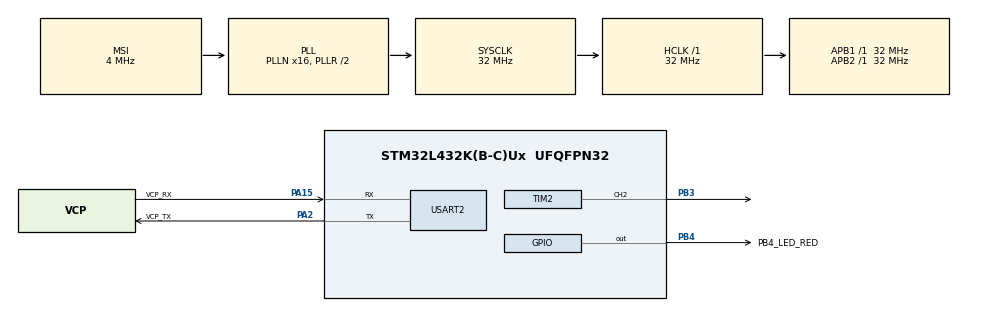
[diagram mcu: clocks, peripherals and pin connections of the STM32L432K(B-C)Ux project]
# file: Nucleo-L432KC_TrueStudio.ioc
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Mcu.Family=STM32L4
Mcu.Name=STM32L432K(B-C)Ux
Mcu.Package=UFQFPN32
NVIC.PriorityGroup=NVIC_PRIORITYGROUP_4
PA0.GPIO_Label=MCO [High speed clock in]
PA0.Mode=HSE-External-Clock-Source-for-LittleOrca
PA0.Signal=RCC_CK_IN
PA13\ (JTMS-SWDIO).GPIO_Label=SWDIO
PA13\ (JTMS-SWDIO).Mode=Serial_Wire
PA13\ (JTMS-SWDIO).Signal=SYS_JTMS-SWDIO
PA14\ (JTCK-SWCLK).GPIO_Label=SWCLK
PA14\ (JTCK-SWCLK).Mode=Serial_Wire
PA14\ (JTCK-SWCLK).Signal=SYS_JTCK-SWCLK
PA15\ (JTDI).GPIO_Label=VCP_RX
PA15\ (JTDI).Mode=Asynchronous
PA15\ (JTDI).Signal=USART2_RX
PA2.GPIO_Label=VCP_TX
PA2.Mode=Asynchronous
PA2.Signal=USART2_TX
PB3\ (JTDO-TRACESWO).Signal=S_TIM2_CH2
PB4\ (NJTRST).GPIO_Label=PB4_LED_RED
PB4\ (NJTRST).Signal=GPIO_Output
PC14-OSC32_IN\ (PC14).Mode=LSE-External-Oscillator
PC14-OSC32_IN\ (PC14).Signal=RCC_OSC32_IN
PC15-OSC32_OUT\ (PC15).Mode=LSE-External-Oscillator
PC15-OSC32_OUT\ (PC15).Signal=RCC_OSC32_OUT
ProjectManager.HeapSize=0x200
ProjectManager.StackSize=0x400
ProjectManager.TargetToolchain=TrueSTUDIO
RCC.ADCFreq_Value=32000000
RCC.AHBFreq_Value=32000000
RCC.APB1Freq_Value=32000000
RCC.APB1TimFreq_Value=32000000
RCC.APB2Freq_Value=32000000
RCC.APB2TimFreq_Value=32000000
RCC.CortexFreq_Value=32000000
RCC.HCLKFreq_Value=32000000
RCC.HSE_VALUE=8000000
RCC.HSI16_VALUE=16000000
RCC.HSI48_VALUE=48000000
RCC.HSI_VALUE=16000000
RCC.MSI_VALUE=4000000
RCC.PLLMUL=RCC_PLLMUL_4
RCC.PLLN=16
RCC.PLLSAI1N=16
RCC.SYSCLKFreq_VALUE=32000000
RCC.SYSCLKSource=RCC_SYSCLKSOURCE_PLLCLK
RCC.USBFreq_Value=32000000
RCC.VCOOutputFreq_Value=64000000
SH.S_TIM2_CH2.0=TIM2_CH2,PWM Generation2 CH2
TIM2.Channel-PWM\ Generation2\ CH2=TIM_CHANNEL_2
TIM2.Period=255
TIM2.Prescaler=10
USART2.VirtualMode-Asynchronous=VM_ASYNC
VP_TIM2_VS_ClockSourceINT.Mode=Internal
board=NUCLEO-L432KC

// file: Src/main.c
/**
  ******************************************************************************
  * @file           : main.c
  * @brief          : Main program body
  ******************************************************************************
  ** This notice applies to any and all portions of this file
  * that are not between comment pairs USER CODE BEGIN and
  * USER CODE END. Other portions of this file, whether
  * inserted by the user or by software development tools
  * are owned by their respective copyright owners.
  *
  * COPYRIGHT(c) 2018 STMicroelectronics
  *
  * Redistribution and use in source and binary forms, with or without modification,
  * are permitted provided that the following conditions are met:
  *   1. Redistributions of source code must retain the above copyright notice,
  *      this list of conditions and the following disclaimer.
  *   2. Redistributions in binary form must reproduce the above copyright notice,
  *      this list of conditions and the following disclaimer in the documentation
  *      and/or other materials provided with the distribution.
  *   3. Neither the name of STMicroelectronics nor the names of its contributors
  *      may be used to endorse or promote products derived from this software
  *      without specific prior written permission.
  *
  * THIS SOFTWARE IS PROVIDED BY THE COPYRIGHT HOLDERS AND CONTRIBUTORS "AS IS"
  * AND ANY EXPRESS OR IMPLIED WARRANTIES, INCLUDING, BUT NOT LIMITED TO, THE
  * IMPLIED WARRANTIES OF MERCHANTABILITY AND FITNESS FOR A PARTICULAR PURPOSE ARE
  * DISCLAIMED. IN NO EVENT SHALL THE COPYRIGHT HOLDER OR CONTRIBUTORS BE LIABLE
  * FOR ANY DIRECT, INDIRECT, INCIDENTAL, SPECIAL, EXEMPLARY, OR CONSEQUENTIAL
  * DAMAGES (INCLUDING, BUT NOT LIMITED TO, PROCUREMENT OF SUBSTITUTE GOODS OR
  * SERVICES; LOSS OF USE, DATA, OR PROFITS; OR BUSINESS INTERRUPTION) HOWEVER
  * CAUSED AND ON ANY THEORY OF LIABILITY, WHETHER IN CONTRACT, STRICT LIABILITY,
  * OR TORT (INCLUDING NEGLIGENCE OR OTHERWISE) ARISING IN ANY WAY OUT OF THE USE
  * OF THIS SOFTWARE, EVEN IF ADVISED OF THE POSSIBILITY OF SUCH DAMAGE.
  *
  ******************************************************************************
  */
#include "main.h"
#include "stm32l4xx_hal.h"

TIM_HandleTypeDef htim2;

UART_HandleTypeDef huart2;

/* USER CODE BEGIN PV */
/* Private variables ---------------------------------------------------------*/

/* USER CODE END PV */

void SystemClock_Config(void);
static void MX_GPIO_Init(void);
static void MX_USART2_UART_Init(void);
static void MX_TIM2_Init(void);
void HAL_TIM_MspPostInit(TIM_HandleTypeDef *htim);

/* USER CODE BEGIN PFP */
/* Private function prototypes -----------------------------------------------*/

/* USER CODE END PFP */

int main(void)
{

  /* MCU Configuration----------------------------------------------------------*/

  /* Reset of all peripherals, Initializes the Flash interface and the Systick. */
  HAL_Init();

  /* Configure the system clock */
  SystemClock_Config();

  /* Initialize all configured peripherals */
  MX_GPIO_Init();
  MX_USART2_UART_Init();
  MX_TIM2_Init();
  /* USER CODE BEGIN 2 */

  // PWM modulation
  HAL_TIM_PWM_Start(&htim2, TIM_CHANNEL_2);

  /* USER CODE END 2 */

  /* Infinite loop */
  /* USER CODE BEGIN WHILE */
  uint8_t cnt = 0;
  while (1)
  {
	  // Simple LED blinking
	  //HAL_GPIO_TogglePin(GPIOB, GPIO_PIN_3);
	  //HAL_Delay(500);

//	  // Simple LED blinking - alternative
//	  HAL_GPIO_WritePin(GPIOB, GPIO_PIN_3, 0);
//	  HAL_Delay(500);
//	  HAL_GPIO_WritePin(GPIOB, GPIO_PIN_3, 1);
//	  HAL_Delay(500);

	  // PWM modulation
	  cnt++;
	  __HAL_TIM_SET_COMPARE(&htim2, TIM_CHANNEL_2, cnt);
	  HAL_Delay(10);

	  // GPIO - Read button SW1 -> Write to LED L_R
	  HAL_GPIO_WritePin(GPIOB, GPIO_PIN_4, HAL_GPIO_ReadPin(GPIOA, GPIO_PIN_12));

  /* USER CODE END WHILE */

  }

}

void SystemClock_Config(void)
{

  RCC_OscInitTypeDef RCC_OscInitStruct;
  RCC_ClkInitTypeDef RCC_ClkInitStruct;
  RCC_PeriphCLKInitTypeDef PeriphClkInit;

    /**Configure LSE Drive Capability
    */
  HAL_PWR_EnableBkUpAccess();

  __HAL_RCC_LSEDRIVE_CONFIG(RCC_LSEDRIVE_LOW);

    /**Initializes the CPU, AHB and APB busses clocks
    */
  RCC_OscInitStruct.OscillatorType = RCC_OSCILLATORTYPE_LSE|RCC_OSCILLATORTYPE_MSI;
  RCC_OscInitStruct.LSEState = RCC_LSE_ON;
  RCC_OscInitStruct.MSIState = RCC_MSI_ON;
  RCC_OscInitStruct.MSICalibrationValue = 0;
  RCC_OscInitStruct.MSIClockRange = RCC_MSIRANGE_6;
  RCC_OscInitStruct.PLL.PLLState = RCC_PLL_ON;
  RCC_OscInitStruct.PLL.PLLSource = RCC_PLLSOURCE_MSI;
  RCC_OscInitStruct.PLL.PLLN = 16;
  RCC_OscInitStruct.PLL.PLLP = RCC_PLLP_DIV7;
  RCC_OscInitStruct.PLL.PLLQ = RCC_PLLQ_DIV2;
  RCC_OscInitStruct.PLL.PLLR = RCC_PLLR_DIV2;
  if (HAL_RCC_OscConfig(&RCC_OscInitStruct) != HAL_OK)
  {
    _Error_Handler(__FILE__, __LINE__);
  }

    /**Initializes the CPU, AHB and APB busses clocks
    */
  RCC_ClkInitStruct.ClockType = RCC_CLOCKTYPE_HCLK|RCC_CLOCKTYPE_SYSCLK
                              |RCC_CLOCKTYPE_PCLK1|RCC_CLOCKTYPE_PCLK2;
  RCC_ClkInitStruct.SYSCLKSource = RCC_SYSCLKSOURCE_PLLCLK;
  RCC_ClkInitStruct.AHBCLKDivider = RCC_SYSCLK_DIV1;
  RCC_ClkInitStruct.APB1CLKDivider = RCC_HCLK_DIV1;
  RCC_ClkInitStruct.APB2CLKDivider = RCC_HCLK_DIV1;

  if (HAL_RCC_ClockConfig(&RCC_ClkInitStruct, FLASH_LATENCY_1) != HAL_OK)
  {
    _Error_Handler(__FILE__, __LINE__);
  }

  PeriphClkInit.PeriphClockSelection = RCC_PERIPHCLK_USART2;
  PeriphClkInit.Usart2ClockSelection = RCC_USART2CLKSOURCE_PCLK1;
  if (HAL_RCCEx_PeriphCLKConfig(&PeriphClkInit) != HAL_OK)
  {
    _Error_Handler(__FILE__, __LINE__);
  }

    /**Configure the main internal regulator output voltage
    */
  if (HAL_PWREx_ControlVoltageScaling(PWR_REGULATOR_VOLTAGE_SCALE1) != HAL_OK)
  {
    _Error_Handler(__FILE__, __LINE__);
  }

    /**Configure the Systick interrupt time
    */
  HAL_SYSTICK_Config(HAL_RCC_GetHCLKFreq()/1000);

    /**Configure the Systick
    */
  HAL_SYSTICK_CLKSourceConfig(SYSTICK_CLKSOURCE_HCLK);

    /**Enable MSI Auto calibration
    */
  HAL_RCCEx_EnableMSIPLLMode();

  /* SysTick_IRQn interrupt configuration */
  HAL_NVIC_SetPriority(SysTick_IRQn, 0, 0);
}

/* TIM2 init function */
static void MX_TIM2_Init(void)
{

  TIM_ClockConfigTypeDef sClockSourceConfig;
  TIM_MasterConfigTypeDef sMasterConfig;
  TIM_OC_InitTypeDef sConfigOC;

  htim2.Instance = TIM2;
  htim2.Init.Prescaler = 10;
  htim2.Init.CounterMode = TIM_COUNTERMODE_UP;
  htim2.Init.Period = 255;
  htim2.Init.ClockDivision = TIM_CLOCKDIVISION_DIV1;
  htim2.Init.AutoReloadPreload = TIM_AUTORELOAD_PRELOAD_DISABLE;
  if (HAL_TIM_Base_Init(&htim2) != HAL_OK)
  {
    _Error_Handler(__FILE__, __LINE__);
  }

  sClockSourceConfig.ClockSource = TIM_CLOCKSOURCE_INTERNAL;
  if (HAL_TIM_ConfigClockSource(&htim2, &sClockSourceConfig) != HAL_OK)
  {
    _Error_Handler(__FILE__, __LINE__);
  }

  if (HAL_TIM_PWM_Init(&htim2) != HAL_OK)
  {
    _Error_Handler(__FILE__, __LINE__);
  }

  sMasterConfig.MasterOutputTrigger = TIM_TRGO_RESET;
  sMasterConfig.MasterSlaveMode = TIM_MASTERSLAVEMODE_DISABLE;
  if (HAL_TIMEx_MasterConfigSynchronization(&htim2, &sMasterConfig) != HAL_OK)
  {
    _Error_Handler(__FILE__, __LINE__);
  }

  sConfigOC.OCMode = TIM_OCMODE_PWM1;
  sConfigOC.Pulse = 0;
  sConfigOC.OCPolarity = TIM_OCPOLARITY_HIGH;
  sConfigOC.OCFastMode = TIM_OCFAST_DISABLE;
  if (HAL_TIM_PWM_ConfigChannel(&htim2, &sConfigOC, TIM_CHANNEL_2) != HAL_OK)
  {
    _Error_Handler(__FILE__, __LINE__);
  }

  HAL_TIM_MspPostInit(&htim2);

}

/* USART2 init function */
static void MX_USART2_UART_Init(void)
{

  huart2.Instance = USART2;
  huart2.Init.BaudRate = 115200;
  huart2.Init.WordLength = UART_WORDLENGTH_7B;
  huart2.Init.StopBits = UART_STOPBITS_1;
  huart2.Init.Parity = UART_PARITY_NONE;
  huart2.Init.Mode = UART_MODE_TX_RX;
  huart2.Init.HwFlowCtl = UART_HWCONTROL_NONE;
  huart2.Init.OverSampling = UART_OVERSAMPLING_16;
  huart2.Init.OneBitSampling = UART_ONE_BIT_SAMPLE_DISABLE;
  huart2.AdvancedInit.AdvFeatureInit = UART_ADVFEATURE_NO_INIT;
  if (HAL_UART_Init(&huart2) != HAL_OK)
  {
    _Error_Handler(__FILE__, __LINE__);
  }

}

/** Configure pins as
        * Analog
        * Input
        * Output
        * EVENT_OUT
        * EXTI
*/
static void MX_GPIO_Init(void)
{

  GPIO_InitTypeDef GPIO_InitStruct;

  /* GPIO Ports Clock Enable */
  __HAL_RCC_GPIOC_CLK_ENABLE();
  __HAL_RCC_GPIOA_CLK_ENABLE();
  __HAL_RCC_GPIOB_CLK_ENABLE();

  /*Configure GPIO pin Output Level */
  HAL_GPIO_WritePin(PB4_LED_RED_GPIO_Port, PB4_LED_RED_Pin, GPIO_PIN_RESET);

  /*Configure GPIO pin : PB4_LED_RED_Pin */
  GPIO_InitStruct.Pin = PB4_LED_RED_Pin;
  GPIO_InitStruct.Mode = GPIO_MODE_OUTPUT_PP;
  GPIO_InitStruct.Pull = GPIO_NOPULL;
  GPIO_InitStruct.Speed = GPIO_SPEED_FREQ_LOW;
  HAL_GPIO_Init(PB4_LED_RED_GPIO_Port, &GPIO_InitStruct);

}

void _Error_Handler(char *file, int line)
{
  while(1)
  {
  }
}

/************************ (C) COPYRIGHT STMicroelectronics *****END OF FILE****/
